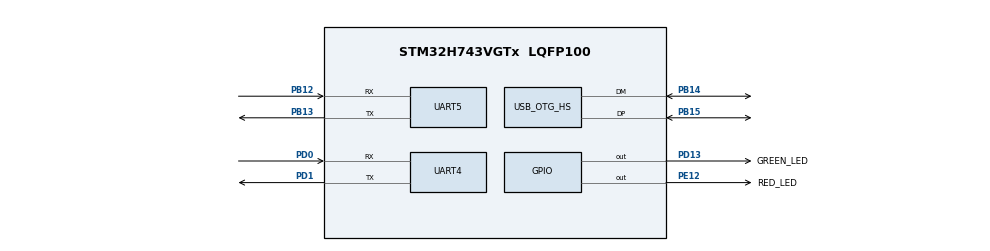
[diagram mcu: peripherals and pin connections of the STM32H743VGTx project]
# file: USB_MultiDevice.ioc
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AL94.I-CUBE-USBD-COMPOSITE.1.0.3.CompositeCcUSBJjCOMPOSITEJjCDCIiACM=true
AL94.I-CUBE-USBD-COMPOSITE.1.0.3.CompositeCcUSBJjCOMPOSITEJjCDCIiECM=true
AL94.I-CUBE-USBD-COMPOSITE.1.0.3.CompositeCcUSBJjCOMPOSITEJjCDCIiRNDIS=true
AL94.I-CUBE-USBD-COMPOSITE.1.0.3.CompositeCcUSBJjCOMPOSITEJjCOMPOSITE=true
AL94.I-CUBE-USBD-COMPOSITE.1.0.3.CompositeCcUSBJjCOMPOSITEJjCore=true
AL94.I-CUBE-USBD-COMPOSITE.1.0.3.CompositeCcUSBJjCOMPOSITEJjDFU=true
AL94.I-CUBE-USBD-COMPOSITE.1.0.3.CompositeCcUSBJjCOMPOSITEJjHIDIiCUSTOM=true
AL94.I-CUBE-USBD-COMPOSITE.1.0.3.CompositeCcUSBJjCOMPOSITEJjHIDIiKEYBOARD=true
AL94.I-CUBE-USBD-COMPOSITE.1.0.3.CompositeCcUSBJjCOMPOSITEJjHIDIiMOUSE=true
AL94.I-CUBE-USBD-COMPOSITE.1.0.3.CompositeCcUSBJjCOMPOSITEJjMSCIiBOT=true
AL94.I-CUBE-USBD-COMPOSITE.1.0.3.CompositeCcUSBJjCOMPOSITEJjPRINTER=true
AL94.I-CUBE-USBD-COMPOSITE.1.0.3.CompositeCcUSBJjCOMPOSITEJjUACIiMIC=true
AL94.I-CUBE-USBD-COMPOSITE.1.0.3.CompositeCcUSBJjCOMPOSITEJjUACIiSPKR=true
AL94.I-CUBE-USBD-COMPOSITE.1.0.3.CompositeCcUSBJjCOMPOSITEJjUVC=true
AL94.I-CUBE-USBD-COMPOSITE.1.0.3._USBD_CDC_ACM_COUNT=2
AL94.I-CUBE-USBD-COMPOSITE.1.0.3._USBD_USE_CDC_ACM=true
AL94.I-CUBE-USBD-COMPOSITE.1.0.3._USBD_USE_HID_CUSTOM=true
AL94.I-CUBE-USBD-COMPOSITE.1.0.3._USBD_USE_HID_MOUSE=false
AL94.I-CUBE-USBD-COMPOSITE.1.0.3._USBD_USE_HS=true
CORTEX_M7.default_mode_Activation=1
Mcu.Family=STM32H7
Mcu.Name=STM32H743VGTx
Mcu.Package=LQFP100
NVIC.OTG_HS_IRQn=true\:0\:0\:false\:false\:true\:true\:true\:true
NVIC.PriorityGroup=NVIC_PRIORITYGROUP_4
PA13\ (JTMS/SWDIO).Mode=Serial_Wire
PA13\ (JTMS/SWDIO).Signal=DEBUG_JTMS-SWDIO
PA14\ (JTCK/SWCLK).Mode=Serial_Wire
PA14\ (JTCK/SWCLK).Signal=DEBUG_JTCK-SWCLK
PB12.Mode=Asynchronous
PB12.Signal=UART5_RX
PB13.Mode=Asynchronous
PB13.Signal=UART5_TX
PB14.Mode=Device_Only_FS
PB14.Signal=USB_OTG_HS_DM
PB15.Mode=Device_Only_FS
PB15.Signal=USB_OTG_HS_DP
PD0.Mode=Asynchronous
PD0.Signal=UART4_RX
PD1.Mode=Asynchronous
PD1.Signal=UART4_TX
PD13.GPIO_Label=GREEN_LED
PD13.PinState=GPIO_PIN_SET
PD13.Signal=GPIO_Output
PE12.GPIO_Label=RED_LED
PE12.PinState=GPIO_PIN_SET
PE12.Signal=GPIO_Output
PH0-OSC_IN\ (PH0).Mode=HSE-External-Oscillator
PH0-OSC_IN\ (PH0).Signal=RCC_OSC_IN
PH1-OSC_OUT\ (PH1).Mode=HSE-External-Oscillator
PH1-OSC_OUT\ (PH1).Signal=RCC_OSC_OUT
ProjectManager.HeapSize=0x2000
ProjectManager.StackSize=0x4000
ProjectManager.TargetToolchain=CMake
RCC.ADCFreq_Value=50390625
RCC.APB1Freq_Value=120000000
RCC.APB2Freq_Value=120000000
RCC.APB3Freq_Value=120000000
RCC.APB4Freq_Value=120000000
RCC.CortexFreq_Value=480000000
RCC.D1PPRE=RCC_APB3_DIV2
RCC.D2PPRE1=RCC_APB1_DIV2
RCC.D2PPRE2=RCC_APB2_DIV2
RCC.D3PPRE=RCC_APB4_DIV2
RCC.DIVM1=5
RCC.DIVN1=192
RCC.DIVQ1=20
RCC.HCLKFreq_Value=240000000
RCC.HPRE=RCC_HCLK_DIV2
RCC.PLL2FRACN=0
RCC.PLL3FRACN=0
RCC.PLLFRACN=0
RCC.PLLSourceVirtual=RCC_PLLSOURCE_HSE
RCC.SYSCLKFreq_VALUE=480000000
RCC.SYSCLKSource=RCC_SYSCLKSOURCE_PLLCLK
RCC.USBFreq_Value=48000000
USB_OTG_HS.VirtualMode-Device_Only_FS=Device_Only_FS
VP_AL94.I-CUBE-USBD-COMPOSITE_VS_USBJjComposite_1.0.0_1.0.3.Mode=USBJjComposite
VP_MEMORYMAP_VS_MEMORYMAP.Mode=CurAppReg
board=custom

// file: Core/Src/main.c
/* USER CODE BEGIN Header */
/**
  ******************************************************************************
  * @file           : main.c
  * @brief          : Main program body
  ******************************************************************************
  * @attention
  *
  * Copyright (c) 2025 STMicroelectronics.
  * All rights reserved.
  *
  * This software is licensed under terms that can be found in the LICENSE file
  * in the root directory of this software component.
  * If no LICENSE file comes with this software, it is provided AS-IS.
  *
  ******************************************************************************
  */
/* USER CODE END Header */
#include "main.h"
#include "memorymap.h"
#include "usart.h"
#include "usb_otg.h"
#include "gpio.h"

/* USER CODE BEGIN Includes */
#include "usb_device.h"
/* USER CODE END Includes */

void SystemClock_Config(void);
static void MPU_Config(void);

/* USER CODE BEGIN 0 */
uint8_t data[] = "Hello Baby!\r\n";

/* USER CODE END 0 */

int main(void)
{

  /* MPU Configuration--------------------------------------------------------*/
  MPU_Config();

  /* MCU Configuration--------------------------------------------------------*/

  /* Reset of all peripherals, Initializes the Flash interface and the Systick. */
  HAL_Init();

  /* Configure the system clock */
  SystemClock_Config();

  /* Initialize all configured peripherals */
  MX_GPIO_Init();
  MX_UART4_Init();
  MX_UART5_Init();
  MX_USB_OTG_HS_PCD_Init();
  /* USER CODE BEGIN 2 */
  MX_USB_DEVICE_Init();
  /* USER CODE END 2 */

  /* Infinite loop */
  /* USER CODE BEGIN WHILE */
  while (1)
  {
    LL_GPIO_ResetOutputPin(GREEN_LED_GPIO_Port, GREEN_LED_Pin);
    HAL_Delay(1000);
    LL_GPIO_SetOutputPin(GREEN_LED_GPIO_Port, GREEN_LED_Pin);
    HAL_Delay(1000);
    /* USER CODE END WHILE */

  }
}

void SystemClock_Config(void)
{
  LL_FLASH_SetLatency(LL_FLASH_LATENCY_4);
  while(LL_FLASH_GetLatency()!= LL_FLASH_LATENCY_4)
  {
  }
  LL_PWR_ConfigSupply(LL_PWR_LDO_SUPPLY);
  LL_PWR_SetRegulVoltageScaling(LL_PWR_REGU_VOLTAGE_SCALE0);
  while (LL_PWR_IsActiveFlag_VOS() == 0)
  {
  }
  LL_RCC_HSE_Enable();

   /* Wait till HSE is ready */
  while(LL_RCC_HSE_IsReady() != 1)
  {

  }
  LL_RCC_PLL_SetSource(LL_RCC_PLLSOURCE_HSE);
  LL_RCC_PLL1P_Enable();
  LL_RCC_PLL1Q_Enable();
  LL_RCC_PLL1R_Enable();
  LL_RCC_PLL1_SetVCOInputRange(LL_RCC_PLLINPUTRANGE_4_8);
  LL_RCC_PLL1_SetVCOOutputRange(LL_RCC_PLLVCORANGE_WIDE);
  LL_RCC_PLL1_SetM(5);
  LL_RCC_PLL1_SetN(192);
  LL_RCC_PLL1_SetP(2);
  LL_RCC_PLL1_SetQ(20);
  LL_RCC_PLL1_SetR(2);
  LL_RCC_PLL1_Enable();

   /* Wait till PLL is ready */
  while(LL_RCC_PLL1_IsReady() != 1)
  {
  }

   /* Intermediate AHB prescaler 2 when target frequency clock is higher than 80 MHz */
   LL_RCC_SetAHBPrescaler(LL_RCC_AHB_DIV_2);

  LL_RCC_SetSysClkSource(LL_RCC_SYS_CLKSOURCE_PLL1);

   /* Wait till System clock is ready */
  while(LL_RCC_GetSysClkSource() != LL_RCC_SYS_CLKSOURCE_STATUS_PLL1)
  {

  }
  LL_RCC_SetSysPrescaler(LL_RCC_SYSCLK_DIV_1);
  LL_RCC_SetAHBPrescaler(LL_RCC_AHB_DIV_2);
  LL_RCC_SetAPB1Prescaler(LL_RCC_APB1_DIV_2);
  LL_RCC_SetAPB2Prescaler(LL_RCC_APB2_DIV_2);
  LL_RCC_SetAPB3Prescaler(LL_RCC_APB3_DIV_2);
  LL_RCC_SetAPB4Prescaler(LL_RCC_APB4_DIV_2);
  LL_SetSystemCoreClock(480000000);

   /* Update the time base */
  if (HAL_InitTick (TICK_INT_PRIORITY) != HAL_OK)
  {
    Error_Handler();
  }
}

 /* MPU Configuration */

void MPU_Config(void)
{

  /* Disables the MPU */
  LL_MPU_Disable();

  /** Initializes and configures the Region and the memory to be protected
  */
  LL_MPU_ConfigRegion(LL_MPU_REGION_NUMBER0, 0x87, 0x0, LL_MPU_REGION_SIZE_4GB|LL_MPU_TEX_LEVEL0|LL_MPU_REGION_NO_ACCESS|LL_MPU_INSTRUCTION_ACCESS_DISABLE|LL_MPU_ACCESS_SHAREABLE|LL_MPU_ACCESS_NOT_CACHEABLE|LL_MPU_ACCESS_NOT_BUFFERABLE);
  /* Enables the MPU */
  LL_MPU_Enable(LL_MPU_CTRL_PRIVILEGED_DEFAULT);

}

void Error_Handler(void)
{
  __disable_irq();
  while (1)
  {
  }
}
